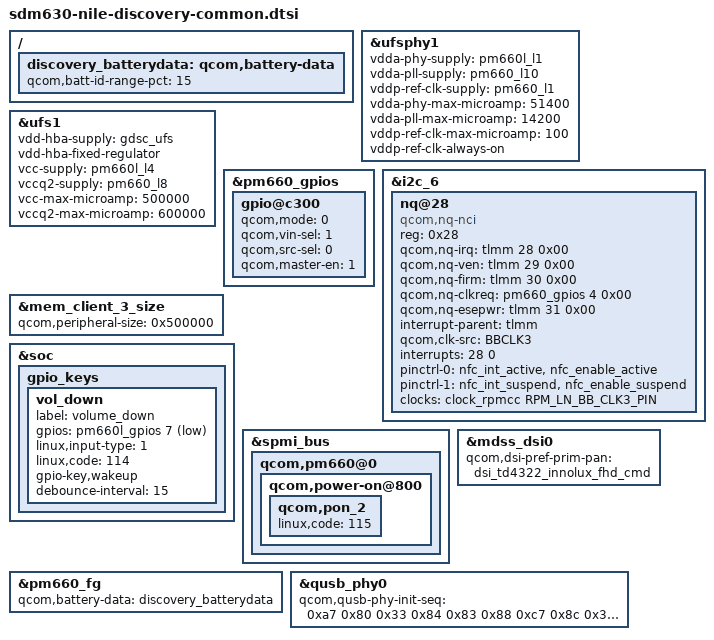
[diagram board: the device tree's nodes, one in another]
/* Copyright (c) 2017, The Linux Foundation. All rights reserved.
 *
 * This program is free software; you can redistribute it and/or modify
 * it under the terms of the GNU General Public License version 2 and
 * only version 2 as published by the Free Software Foundation.
 *
 * This program is distributed in the hope that it will be useful,
 * but WITHOUT ANY WARRANTY; without even the implied warranty of
 * MERCHANTABILITY or FITNESS FOR A PARTICULAR PURPOSE.  See the
 * GNU General Public License for more details.
 */

/ {
	discovery_batterydata: qcom,battery-data {
		qcom,batt-id-range-pct = <15>;
		#include "fg-gen3-batterydata-3450mah.dtsi"
	};
};

&ufsphy1 {
	vdda-phy-supply = <&pm660l_l1>;
	vdda-pll-supply = <&pm660_l10>;
	vddp-ref-clk-supply = <&pm660_l1>;
	vdda-phy-max-microamp = <51400>;
	vdda-pll-max-microamp = <14200>;
	vddp-ref-clk-max-microamp = <100>;
	vddp-ref-clk-always-on;
	status = "ok";
};

&ufs1 {
	vdd-hba-supply = <&gdsc_ufs>;
	vdd-hba-fixed-regulator;
	vcc-supply = <&pm660l_l4>;
	vccq2-supply = <&pm660_l8>;
	vcc-max-microamp = <500000>;
	vccq2-max-microamp = <600000>;
	status = "ok";
};

&pm660_gpios {
	/* GPIO 4 (NFC_CLK_REQ) */
	gpio@c300 {
		qcom,mode = <0>;
		qcom,vin-sel = <1>;
		qcom,src-sel = <0>;
		qcom,master-en = <1>;
		status = "okay";
	};
};

&i2c_6 { /* BLSP1 QUP6 (NFC) */
	status = "okay";
	nq@28 {
		compatible = "qcom,nq-nci";
		reg = <0x28>;
		qcom,nq-irq = <&tlmm 28 0x00>;
		qcom,nq-ven = <&tlmm 29 0x00>;
		qcom,nq-firm = <&tlmm 30 0x00>;
		qcom,nq-clkreq = <&pm660_gpios 4 0x00>;
		qcom,nq-esepwr = <&tlmm 31 0x00>;
		interrupt-parent = <&tlmm>;
		qcom,clk-src = "BBCLK3";
		interrupts = <28 0>;
		interrupt-names = "nfc_irq";
		pinctrl-names = "nfc_active", "nfc_suspend";
		pinctrl-0 = <&nfc_int_active &nfc_enable_active>;
		pinctrl-1 = <&nfc_int_suspend &nfc_enable_suspend>;
		clocks = <&clock_rpmcc RPM_LN_BB_CLK3_PIN>;
		clock-names = "ref_clk";
	};
};

&mem_client_3_size {
	qcom,peripheral-size = <0x500000>;
};

&soc {
	gpio_keys {
		/delete-node/ vol_up;

		vol_down {
			label = "volume_down";
			gpios = <&pm660l_gpios 7 0x1>;
			linux,input-type = <1>;
			linux,code = <114>;
			gpio-key,wakeup;
			debounce-interval = <15>;
		};
	};
};

&spmi_bus {
	qcom,pm660@0 {
		qcom,power-on@800 {
			/delete-property/ kpdpwr-sw-debounce;
			qcom,pon_2 {
				linux,code = <115>;
			};
		};
	};
};

&pm660_fg {
	qcom,battery-data = <&discovery_batterydata>;
};

&mdss_dsi0 {
	qcom,dsi-pref-prim-pan = <&dsi_td4322_innolux_fhd_cmd>;
};

&qusb_phy0 {
	qcom,qusb-phy-init-seq = <0xa7 0x80
				  0x33 0x84
				  0x83 0x88
				  0xc7 0x8c
				  0x30 0x08
				  0x79 0x0c
				  0x21 0x10
				  0x14 0x9c
				  0x9f 0x1c
				  0x00 0x18>;
};

